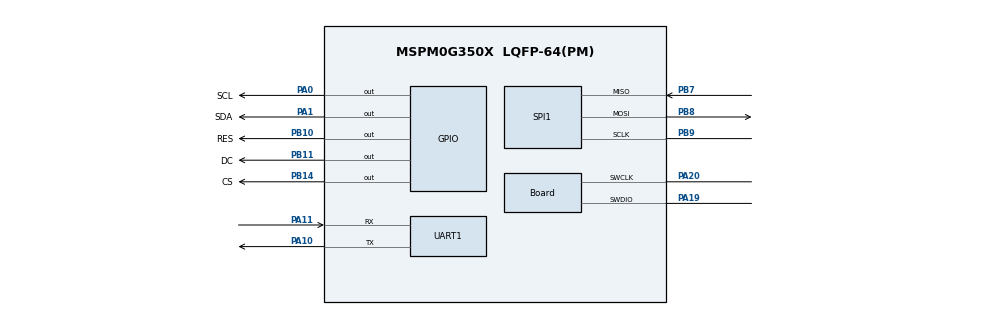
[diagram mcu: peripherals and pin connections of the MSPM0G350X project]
/**
 * @cliArgs --device "MSPM0G350X" --package "LQFP-64(PM)" --part "Default" --product "mspm0_sdk@1.30.00.03"
 * @versions {"tool":"1.19.0+3426"}
 */

/**
 * Import the modules used in this configuration.
 */
const GPIO          = scripting.addModule("/ti/driverlib/GPIO", {}, false);
const GPIO1         = GPIO.addInstance();
const GPIO2         = GPIO.addInstance();
const GPIO3         = GPIO.addInstance();
const GPIO4         = GPIO.addInstance();
const SPI           = scripting.addModule("/ti/driverlib/SPI", {}, false);
const SPI1          = SPI.addInstance();
const SYSCTL        = scripting.addModule("/ti/driverlib/SYSCTL");
const TIMER         = scripting.addModule("/ti/driverlib/TIMER", {}, false);
const TIMER1        = TIMER.addInstance();
const UART          = scripting.addModule("/ti/driverlib/UART", {}, false);
const UART1         = UART.addInstance();
const ProjectConfig = scripting.addModule("/ti/project_config/ProjectConfig");

/**
 * Write custom configuration values to the imported modules.
 */
const gate7  = system.clockTree["MFCLKGATE"];
gate7.enable = true;

GPIO1.$name                          = "LED";
GPIO1.associatedPins.create(3);
GPIO1.associatedPins[0].$name        = "LEDR";
GPIO1.associatedPins[0].assignedPort = "PORTB";
GPIO1.associatedPins[0].assignedPin  = "18";
GPIO1.associatedPins[1].$name        = "LEDG";
GPIO1.associatedPins[1].assignedPort = "PORTB";
GPIO1.associatedPins[1].assignedPin  = "19";
GPIO1.associatedPins[2].$name        = "LEDB";
GPIO1.associatedPins[2].assignedPort = "PORTB";
GPIO1.associatedPins[2].assignedPin  = "22";

const Board                       = scripting.addModule("/ti/driverlib/Board", {}, false);
Board.peripheral.$assign          = "DEBUGSS";
Board.peripheral.swclkPin.$assign = "PA20";
Board.peripheral.swdioPin.$assign = "PA19";

GPIO2.$name                          = "KEY";
GPIO2.associatedPins.create(2);
GPIO2.associatedPins[0].$name        = "KEY0";
GPIO2.associatedPins[0].assignedPort = "PORTA";
GPIO2.associatedPins[0].assignedPin  = "18";
GPIO2.associatedPins[0].direction    = "INPUT";
GPIO2.associatedPins[1].$name        = "KEY1";
GPIO2.associatedPins[1].assignedPort = "PORTB";
GPIO2.associatedPins[1].assignedPin  = "21";
GPIO2.associatedPins[1].direction    = "INPUT";

GPIO3.$name                         = "OLED";
GPIO3.port                          = "PORTB";
GPIO3.associatedPins.create(3);
GPIO3.associatedPins[0].$name       = "RES";
GPIO3.associatedPins[0].ioStructure = "SD";
GPIO3.associatedPins[0].assignedPin = "10";
GPIO3.associatedPins[0].pin.$assign = "PB10";
GPIO3.associatedPins[1].$name       = "DC";
GPIO3.associatedPins[1].ioStructure = "SD";
GPIO3.associatedPins[1].assignedPin = "11";
GPIO3.associatedPins[1].pin.$assign = "PB11";
GPIO3.associatedPins[2].$name       = "CS";
GPIO3.associatedPins[2].ioStructure = "SD";
GPIO3.associatedPins[2].assignedPin = "14";
GPIO3.associatedPins[2].pin.$assign = "PB14";

GPIO4.$name                          = "I2C";
GPIO4.associatedPins.create(2);
GPIO4.associatedPins[0].$name        = "SDA";
GPIO4.associatedPins[0].initialValue = "SET";
GPIO4.associatedPins[0].assignedPort = "PORTA";
GPIO4.associatedPins[0].assignedPin  = "1";
GPIO4.associatedPins[0].pin.$assign  = "PA1";
GPIO4.associatedPins[1].$name        = "SCL";
GPIO4.associatedPins[1].initialValue = "SET";
GPIO4.associatedPins[1].assignedPort = "PORTA";
GPIO4.associatedPins[1].assignedPin  = "0";
GPIO4.associatedPins[1].pin.$assign  = "PA0";

SPI1.$name                              = "SPI_OLED";
SPI1.frameFormat                        = "MOTO3";
SPI1.polarity                           = "1";
SPI1.peripheral.$assign                 = "SPI1";
SPI1.peripheral.sclkPin.$assign         = "PB9";
SPI1.peripheral.mosiPin.$assign         = "PB8";
SPI1.peripheral.misoPin.$assign         = "PB7";
SPI1.sclkPinConfig.direction            = scripting.forceWrite("OUTPUT");
SPI1.sclkPinConfig.onlyInternalResistor = scripting.forceWrite(false);
SPI1.sclkPinConfig.passedPeripheralType = scripting.forceWrite("Digital");
SPI1.sclkPinConfig.$name                = "ti_driverlib_gpio_GPIOPinGeneric2";
SPI1.mosiPinConfig.direction            = scripting.forceWrite("OUTPUT");
SPI1.mosiPinConfig.hideOutputInversion  = scripting.forceWrite(false);
SPI1.mosiPinConfig.onlyInternalResistor = scripting.forceWrite(false);
SPI1.mosiPinConfig.passedPeripheralType = scripting.forceWrite("Digital");
SPI1.mosiPinConfig.$name                = "ti_driverlib_gpio_GPIOPinGeneric3";
SPI1.misoPinConfig.onlyInternalResistor = scripting.forceWrite(false);
SPI1.misoPinConfig.passedPeripheralType = scripting.forceWrite("Digital");
SPI1.misoPinConfig.$name                = "ti_driverlib_gpio_GPIOPinGeneric4";

SYSCTL.clockTreeEn = true;

TIMER1.$name            = "TIMER_0";
TIMER1.timerClkPrescale = 100;
TIMER1.timerMode        = "PERIODIC_UP";
TIMER1.interrupts       = ["ZERO"];
TIMER1.timerPeriod      = "20ms";

UART1.$name                    = "UART_0";
UART1.enabledInterrupts        = ["RX"];
UART1.targetBaudRate           = 115200;
UART1.uartClkSrc               = "MFCLK";
UART1.peripheral.rxPin.$assign = "PA11";
UART1.peripheral.txPin.$assign = "PA10";
UART1.txPinConfig.$name        = "ti_driverlib_gpio_GPIOPinGeneric0";
UART1.rxPinConfig.$name        = "ti_driverlib_gpio_GPIOPinGeneric1";

ProjectConfig.deviceSpin = "MSPM0G3507";
scripting.suppress("Migrating requires going through the Switch Board or Device menu in the Device View section\\.", ProjectConfig, "deviceSpin");

/**
 * Pinmux solution for unlocked pins/peripherals. This ensures that minor changes to the automatic solver in a future
 * version of the tool will not impact the pinmux you originally saw.  These lines can be completely deleted in order to
 * re-solve from scratch.
 */
GPIO1.associatedPins[0].pin.$suggestSolution = "PB18";
GPIO1.associatedPins[1].pin.$suggestSolution = "PB19";
GPIO1.associatedPins[2].pin.$suggestSolution = "PB22";
GPIO2.associatedPins[0].pin.$suggestSolution = "PA18";
GPIO2.associatedPins[1].pin.$suggestSolution = "PB21";
TIMER1.peripheral.$suggestSolution           = "TIMA0";
UART1.peripheral.$suggestSolution            = "UART0";
